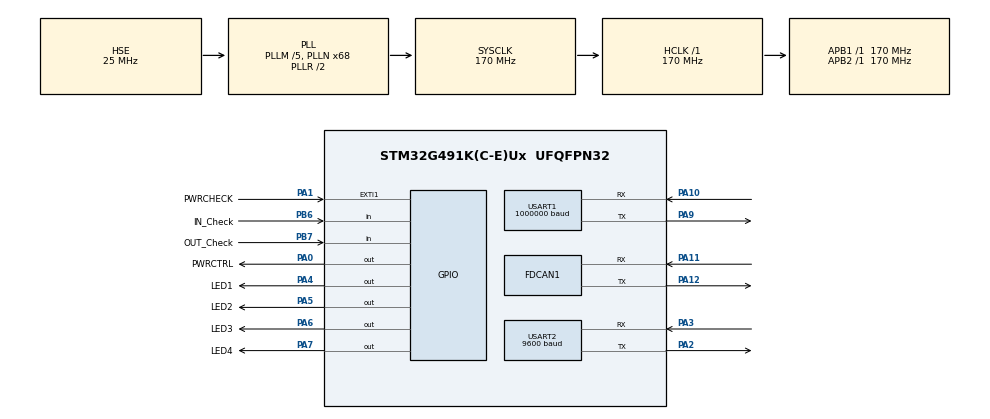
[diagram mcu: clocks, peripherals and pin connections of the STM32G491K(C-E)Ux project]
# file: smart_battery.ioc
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Dma.Request0=USART2_RX
Dma.Request1=USART2_TX
Dma.USART2_RX.0.Direction=DMA_PERIPH_TO_MEMORY
Dma.USART2_RX.0.EventEnable=DISABLE
Dma.USART2_RX.0.Instance=DMA1_Channel1
Dma.USART2_RX.0.MemDataAlignment=DMA_MDATAALIGN_BYTE
Dma.USART2_RX.0.MemInc=DMA_MINC_ENABLE
Dma.USART2_RX.0.Mode=DMA_NORMAL
Dma.USART2_RX.0.PeriphDataAlignment=DMA_PDATAALIGN_BYTE
Dma.USART2_RX.0.PeriphInc=DMA_PINC_DISABLE
Dma.USART2_RX.0.Polarity=HAL_DMAMUX_REQ_GEN_RISING
Dma.USART2_RX.0.Priority=DMA_PRIORITY_LOW
Dma.USART2_RX.0.RequestNumber=1
Dma.USART2_RX.0.SignalID=NONE
Dma.USART2_RX.0.SyncEnable=DISABLE
Dma.USART2_RX.0.SyncPolarity=HAL_DMAMUX_SYNC_NO_EVENT
Dma.USART2_RX.0.SyncRequestNumber=1
Dma.USART2_RX.0.SyncSignalID=NONE
Dma.USART2_TX.1.Direction=DMA_MEMORY_TO_PERIPH
Dma.USART2_TX.1.EventEnable=DISABLE
Dma.USART2_TX.1.Instance=DMA1_Channel2
Dma.USART2_TX.1.MemDataAlignment=DMA_MDATAALIGN_BYTE
Dma.USART2_TX.1.MemInc=DMA_MINC_ENABLE
Dma.USART2_TX.1.Mode=DMA_NORMAL
Dma.USART2_TX.1.PeriphDataAlignment=DMA_PDATAALIGN_BYTE
Dma.USART2_TX.1.PeriphInc=DMA_PINC_DISABLE
Dma.USART2_TX.1.Polarity=HAL_DMAMUX_REQ_GEN_RISING
Dma.USART2_TX.1.Priority=DMA_PRIORITY_LOW
Dma.USART2_TX.1.RequestNumber=1
Dma.USART2_TX.1.SignalID=NONE
Dma.USART2_TX.1.SyncEnable=DISABLE
Dma.USART2_TX.1.SyncPolarity=HAL_DMAMUX_SYNC_NO_EVENT
Dma.USART2_TX.1.SyncRequestNumber=1
Dma.USART2_TX.1.SyncSignalID=NONE
FDCAN1.CalculateBaudRateNominal=999999
FDCAN1.CalculateTimeBitNominal=1000
FDCAN1.CalculateTimeQuantumNominal=29.411764705882355
FDCAN1.DataPrescaler=5
FDCAN1.DataSyncJumpWidth=9
FDCAN1.DataTimeSeg1=24
FDCAN1.DataTimeSeg2=9
FDCAN1.ExtFiltersNbr=8
FDCAN1.FrameFormat=FDCAN_FRAME_FD_BRS
FDCAN1.NominalPrescaler=5
FDCAN1.NominalSyncJumpWidth=9
FDCAN1.NominalTimeSeg1=24
FDCAN1.NominalTimeSeg2=9
FDCAN1.StdFiltersNbr=28
FREERTOS.BinarySemaphores01=PWR_KEY,Dynamic,NULL,Depleted;BMS_RX,Dynamic,NULL,Depleted
FREERTOS.Queues01=bms_send_buf,16,32,1,Dynamic,NULL,NULL
FREERTOS.Tasks01=PowerSwitch,43,512,PowerSwitchTask,Default,NULL,Dynamic,NULL,NULL;SensorRead,24,512,SensorReadTask,Default,NULL,Dynamic,NULL,NULL;DataReport,24,512,DataReportTask,Default,NULL,Dynamic,NULL,NULL;IOUT_CHECK,41,256,IOUT_CHECKTask,Default,NULL,Dynamic,NULL,NULL;LED,24,512,LEDTask,Default,NULL,Dynamic,NULL,NULL
FREERTOS.configTOTAL_HEAP_SIZE=65536
Mcu.Family=STM32G4
Mcu.Name=STM32G491K(C-E)Ux
Mcu.Package=UFQFPN32
NVIC.DMA1_Channel1_IRQn=true\:5\:0\:false\:false\:true\:true\:false\:true\:true
NVIC.DMA1_Channel2_IRQn=true\:5\:0\:false\:false\:true\:true\:false\:true\:true
NVIC.EXTI1_IRQn=true\:5\:0\:false\:false\:true\:true\:true\:true\:true
NVIC.FDCAN1_IT0_IRQn=true\:5\:0\:false\:false\:true\:true\:true\:true\:true
NVIC.PriorityGroup=NVIC_PRIORITYGROUP_4
NVIC.TIM7_IRQn=true\:15\:0\:false\:false\:true\:false\:false\:true\:true
NVIC.TimeBase=TIM7_IRQn
NVIC.TimeBaseIP=TIM7
NVIC.USART2_IRQn=true\:5\:0\:false\:false\:true\:true\:true\:true\:true
PA0.GPIO_Label=PWRCTRL
PA0.GPIO_PuPd=GPIO_PULLDOWN
PA0.GPIO_Speed=GPIO_SPEED_FREQ_VERY_HIGH
PA0.PinState=GPIO_PIN_RESET
PA0.Signal=GPIO_Output
PA1.GPIO_Label=PWRCHECK
PA1.GPIO_ModeDefaultEXTI=GPIO_MODE_IT_FALLING
PA1.GPIO_PuPd=GPIO_PULLUP
PA1.Signal=GPXTI1
PA10.Mode=Asynchronous
PA10.Signal=USART1_RX
PA11.Mode=FDCAN_Activate
PA11.Signal=FDCAN1_RX
PA12.Mode=FDCAN_Activate
PA12.Signal=FDCAN1_TX
PA13.Mode=Serial_Wire
PA13.Signal=SYS_JTMS-SWDIO
PA14.Mode=Serial_Wire
PA14.Signal=SYS_JTCK-SWCLK
PA2.Mode=Asynchronous
PA2.Signal=USART2_TX
PA3.Mode=Asynchronous
PA3.Signal=USART2_RX
PA4.GPIO_Label=LED1
PA4.GPIO_ModeDefaultOutputPP=GPIO_MODE_OUTPUT_PP
PA4.GPIO_PuPd=GPIO_PULLUP
PA4.GPIO_Speed=GPIO_SPEED_FREQ_VERY_HIGH
PA4.PinState=GPIO_PIN_SET
PA4.Signal=GPIO_Output
PA5.GPIO_Label=LED2
PA5.GPIO_PuPd=GPIO_PULLUP
PA5.GPIO_Speed=GPIO_SPEED_FREQ_VERY_HIGH
PA5.PinState=GPIO_PIN_SET
PA5.Signal=GPIO_Output
PA6.GPIO_Label=LED3
PA6.GPIO_PuPd=GPIO_PULLUP
PA6.GPIO_Speed=GPIO_SPEED_FREQ_VERY_HIGH
PA6.PinState=GPIO_PIN_SET
PA6.Signal=GPIO_Output
PA7.GPIO_Label=LED4
PA7.GPIO_PuPd=GPIO_PULLUP
PA7.GPIO_Speed=GPIO_SPEED_FREQ_HIGH
PA7.PinState=GPIO_PIN_SET
PA7.Signal=GPIO_Output
PA9.Mode=Asynchronous
PA9.Signal=USART1_TX
PB6.GPIO_Label=IN_Check
PB6.GPIO_PuPd=GPIO_PULLUP
PB6.Signal=GPIO_Input
PB7.GPIO_Label=OUT_Check
PB7.GPIO_PuPd=GPIO_PULLUP
PB7.Signal=GPIO_Input
PF0-OSC_IN.Mode=HSE-External-Oscillator
PF0-OSC_IN.Signal=RCC_OSC_IN
PF1-OSC_OUT.Mode=HSE-External-Oscillator
PF1-OSC_OUT.Signal=RCC_OSC_OUT
ProjectManager.HeapSize=0x200
ProjectManager.StackSize=0x400
ProjectManager.TargetToolchain=CMake
RCC.ADC12Freq_Value=170000000
RCC.ADC345Freq_Value=170000000
RCC.AHBFreq_Value=170000000
RCC.APB1Freq_Value=170000000
RCC.APB1TimFreq_Value=170000000
RCC.APB2Freq_Value=170000000
RCC.APB2TimFreq_Value=170000000
RCC.CortexFreq_Value=170000000
RCC.EXTERNAL_CLOCK_VALUE=12288000
RCC.HCLKFreq_Value=170000000
RCC.HSE_VALUE=25000000
RCC.HSI48_VALUE=48000000
RCC.HSI_VALUE=16000000
RCC.LSE_VALUE=32768
RCC.PLLM=RCC_PLLM_DIV5
RCC.PLLN=68
RCC.PLLSourceVirtual=RCC_PLLSOURCE_HSE
RCC.SYSCLKFreq_VALUE=170000000
RCC.SYSCLKSource=RCC_SYSCLKSOURCE_PLLCLK
RCC.VCOOutputFreq_Value=340000000
USART1.BaudRate=1000000
USART1.VirtualMode-Asynchronous=VM_ASYNC
USART2.BaudRate=9600
USART2.VirtualMode-Asynchronous=VM_ASYNC
VP_FREERTOS_VS_CMSIS_V2.Mode=CMSIS_V2
VP_SYS_VS_DBSignals.Mode=DisableDeadBatterySignals
VP_SYS_VS_tim7.Mode=TIM7
board=custom

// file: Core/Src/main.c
/* USER CODE BEGIN Header */
/**
  ******************************************************************************
  * @file           : main.c
  * @brief          : Main program body
  ******************************************************************************
  * @attention
  *
  * Copyright (c) 2026 STMicroelectronics.
  * All rights reserved.
  *
  * This software is licensed under terms that can be found in the LICENSE file
  * in the root directory of this software component.
  * If no LICENSE file comes with this software, it is provided AS-IS.
  *
  ******************************************************************************
  */
/* USER CODE END Header */
#include "main.h"
#include "cmsis_os.h"
#include "dma.h"
#include "fdcan.h"
#include "usart.h"
#include "gpio.h"

void SystemClock_Config(void);
void MX_FREERTOS_Init(void);

int main(void)
{

  /* MCU Configuration--------------------------------------------------------*/

  /* Reset of all peripherals, Initializes the Flash interface and the Systick. */
  HAL_Init();

  /* Configure the system clock */
  SystemClock_Config();

  /* Initialize all configured peripherals */
  MX_GPIO_Init();
  MX_DMA_Init();
  MX_USART1_UART_Init();
  MX_USART2_UART_Init();
  MX_FDCAN1_Init();

  /* Init scheduler */
  osKernelInitialize();  /* Call init function for freertos objects (in cmsis_os2.c) */
  MX_FREERTOS_Init();

  /* Start scheduler */
  osKernelStart();

  /* We should never get here as control is now taken by the scheduler */

  /* Infinite loop */
  while (1)
  {

  }
}

void SystemClock_Config(void)
{
  RCC_OscInitTypeDef RCC_OscInitStruct = {0};
  RCC_ClkInitTypeDef RCC_ClkInitStruct = {0};

  /** Configure the main internal regulator output voltage
  */
  HAL_PWREx_ControlVoltageScaling(PWR_REGULATOR_VOLTAGE_SCALE1_BOOST);

  /** Initializes the RCC Oscillators according to the specified parameters
  * in the RCC_OscInitTypeDef structure.
  */
  RCC_OscInitStruct.OscillatorType = RCC_OSCILLATORTYPE_HSE;
  RCC_OscInitStruct.HSEState = RCC_HSE_ON;
  RCC_OscInitStruct.PLL.PLLState = RCC_PLL_ON;
  RCC_OscInitStruct.PLL.PLLSource = RCC_PLLSOURCE_HSE;
  RCC_OscInitStruct.PLL.PLLM = RCC_PLLM_DIV5;
  RCC_OscInitStruct.PLL.PLLN = 68;
  RCC_OscInitStruct.PLL.PLLP = RCC_PLLP_DIV2;
  RCC_OscInitStruct.PLL.PLLQ = RCC_PLLQ_DIV2;
  RCC_OscInitStruct.PLL.PLLR = RCC_PLLR_DIV2;
  if (HAL_RCC_OscConfig(&RCC_OscInitStruct) != HAL_OK)
  {
    Error_Handler();
  }

  /** Initializes the CPU, AHB and APB buses clocks
  */
  RCC_ClkInitStruct.ClockType = RCC_CLOCKTYPE_HCLK|RCC_CLOCKTYPE_SYSCLK
                              |RCC_CLOCKTYPE_PCLK1|RCC_CLOCKTYPE_PCLK2;
  RCC_ClkInitStruct.SYSCLKSource = RCC_SYSCLKSOURCE_PLLCLK;
  RCC_ClkInitStruct.AHBCLKDivider = RCC_SYSCLK_DIV1;
  RCC_ClkInitStruct.APB1CLKDivider = RCC_HCLK_DIV1;
  RCC_ClkInitStruct.APB2CLKDivider = RCC_HCLK_DIV1;

  if (HAL_RCC_ClockConfig(&RCC_ClkInitStruct, FLASH_LATENCY_4) != HAL_OK)
  {
    Error_Handler();
  }
}

void HAL_TIM_PeriodElapsedCallback(TIM_HandleTypeDef *htim)
{
  if (htim->Instance == TIM7)
  {
    HAL_IncTick();
  }
}

void Error_Handler(void)
{
  __disable_irq();
  while (1)
  {
  }
}

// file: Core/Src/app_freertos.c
/* USER CODE BEGIN Header */
/**
  ******************************************************************************
  * File Name          : app_freertos.c
  * Description        : Code for freertos applications
  ******************************************************************************
  * @attention
  *
  * Copyright (c) 2026 STMicroelectronics.
  * All rights reserved.
  *
  * This software is licensed under terms that can be found in the LICENSE file
  * in the root directory of this software component.
  * If no LICENSE file comes with this software, it is provided AS-IS.
  *
  ******************************************************************************
  */
/* USER CODE END Header */

#include "FreeRTOS.h"
#include "task.h"
#include "main.h"
#include "cmsis_os.h"

/* USER CODE BEGIN Includes */
#include "app.h"
/* USER CODE END Includes */

/* Definitions for PowerSwitch */
osThreadId_t PowerSwitchHandle;
const osThreadAttr_t PowerSwitch_attributes = {
  .name = "PowerSwitch",
  .priority = (osPriority_t) osPriorityHigh3,
  .stack_size = 512 * 4
};
/* Definitions for SensorRead */
osThreadId_t SensorReadHandle;
const osThreadAttr_t SensorRead_attributes = {
  .name = "SensorRead",
  .priority = (osPriority_t) osPriorityNormal,
  .stack_size = 512 * 4
};
/* Definitions for DataReport */
osThreadId_t DataReportHandle;
const osThreadAttr_t DataReport_attributes = {
  .name = "DataReport",
  .priority = (osPriority_t) osPriorityNormal,
  .stack_size = 512 * 4
};
/* Definitions for IOUT_CHECK */
osThreadId_t IOUT_CHECKHandle;
const osThreadAttr_t IOUT_CHECK_attributes = {
  .name = "IOUT_CHECK",
  .priority = (osPriority_t) osPriorityHigh1,
  .stack_size = 256 * 4
};
/* Definitions for LED */
osThreadId_t LEDHandle;
const osThreadAttr_t LED_attributes = {
  .name = "LED",
  .priority = (osPriority_t) osPriorityNormal,
  .stack_size = 512 * 4
};
/* Definitions for bms_send_buf */
osMessageQueueId_t bms_send_bufHandle;
const osMessageQueueAttr_t bms_send_buf_attributes = {
  .name = "bms_send_buf"
};
/* Definitions for PWR_KEY */
osSemaphoreId_t PWR_KEYHandle;
const osSemaphoreAttr_t PWR_KEY_attributes = {
  .name = "PWR_KEY"
};
/* Definitions for BMS_RX */
osSemaphoreId_t BMS_RXHandle;
const osSemaphoreAttr_t BMS_RX_attributes = {
  .name = "BMS_RX"
};

void PowerSwitchTask(void *argument);
void SensorReadTask(void *argument);
void DataReportTask(void *argument);
void IOUT_CHECKTask(void *argument);
void LEDTask(void *argument);

void MX_FREERTOS_Init(void); /* (MISRA C 2004 rule 8.1) */

void MX_FREERTOS_Init(void) {
  /* USER CODE BEGIN Init */
  app_init();
  /* USER CODE END Init */

  /* Create the semaphores(s) */
  /* creation of PWR_KEY */
  PWR_KEYHandle = osSemaphoreNew(1, 0, &PWR_KEY_attributes);

  /* creation of BMS_RX */
  BMS_RXHandle = osSemaphoreNew(1, 0, &BMS_RX_attributes);

  /* Create the queue(s) */
  /* creation of bms_send_buf */
  bms_send_bufHandle = osMessageQueueNew (16, 32, &bms_send_buf_attributes);

  /* Create the thread(s) */
  /* creation of PowerSwitch */
  PowerSwitchHandle = osThreadNew(PowerSwitchTask, NULL, &PowerSwitch_attributes);

  /* creation of SensorRead */
  SensorReadHandle = osThreadNew(SensorReadTask, NULL, &SensorRead_attributes);

  /* creation of DataReport */
  DataReportHandle = osThreadNew(DataReportTask, NULL, &DataReport_attributes);

  /* creation of IOUT_CHECK */
  IOUT_CHECKHandle = osThreadNew(IOUT_CHECKTask, NULL, &IOUT_CHECK_attributes);

  /* creation of LED */
  LEDHandle = osThreadNew(LEDTask, NULL, &LED_attributes);

}

void PowerSwitchTask(void *argument)
{
  /* USER CODE BEGIN PowerSwitchTask */
  /* Infinite loop */
  PowerSwitchFunction();
  for(;;)
  {
    osDelay(1);
  }
  /* USER CODE END PowerSwitchTask */
}

void SensorReadTask(void *argument)
{
  /* USER CODE BEGIN SensorReadTask */
  /* Infinite loop */
  SensorReadFunction();
  for(;;)
  {
    osDelay(1);
  }
  /* USER CODE END SensorReadTask */
}

void DataReportTask(void *argument)
{
  /* USER CODE BEGIN DataReportTask */
  /* Infinite loop */
  DataReportFunction();
  for(;;)
  {
    osDelay(1);
  }
  /* USER CODE END DataReportTask */
}

void IOUT_CHECKTask(void *argument)
{
  /* USER CODE BEGIN IOUT_CHECKTask */
  /* Infinite loop */
  IOUT_CHECKFunction();
  for(;;)
  {
    osDelay(1);
  }
  /* USER CODE END IOUT_CHECKTask */
}

void LEDTask(void *argument)
{
  /* USER CODE BEGIN LEDTask */
  /* Infinite loop */
  LEDFunction();
  for(;;)
  {
    osDelay(1);
  }
  /* USER CODE END LEDTask */
}
